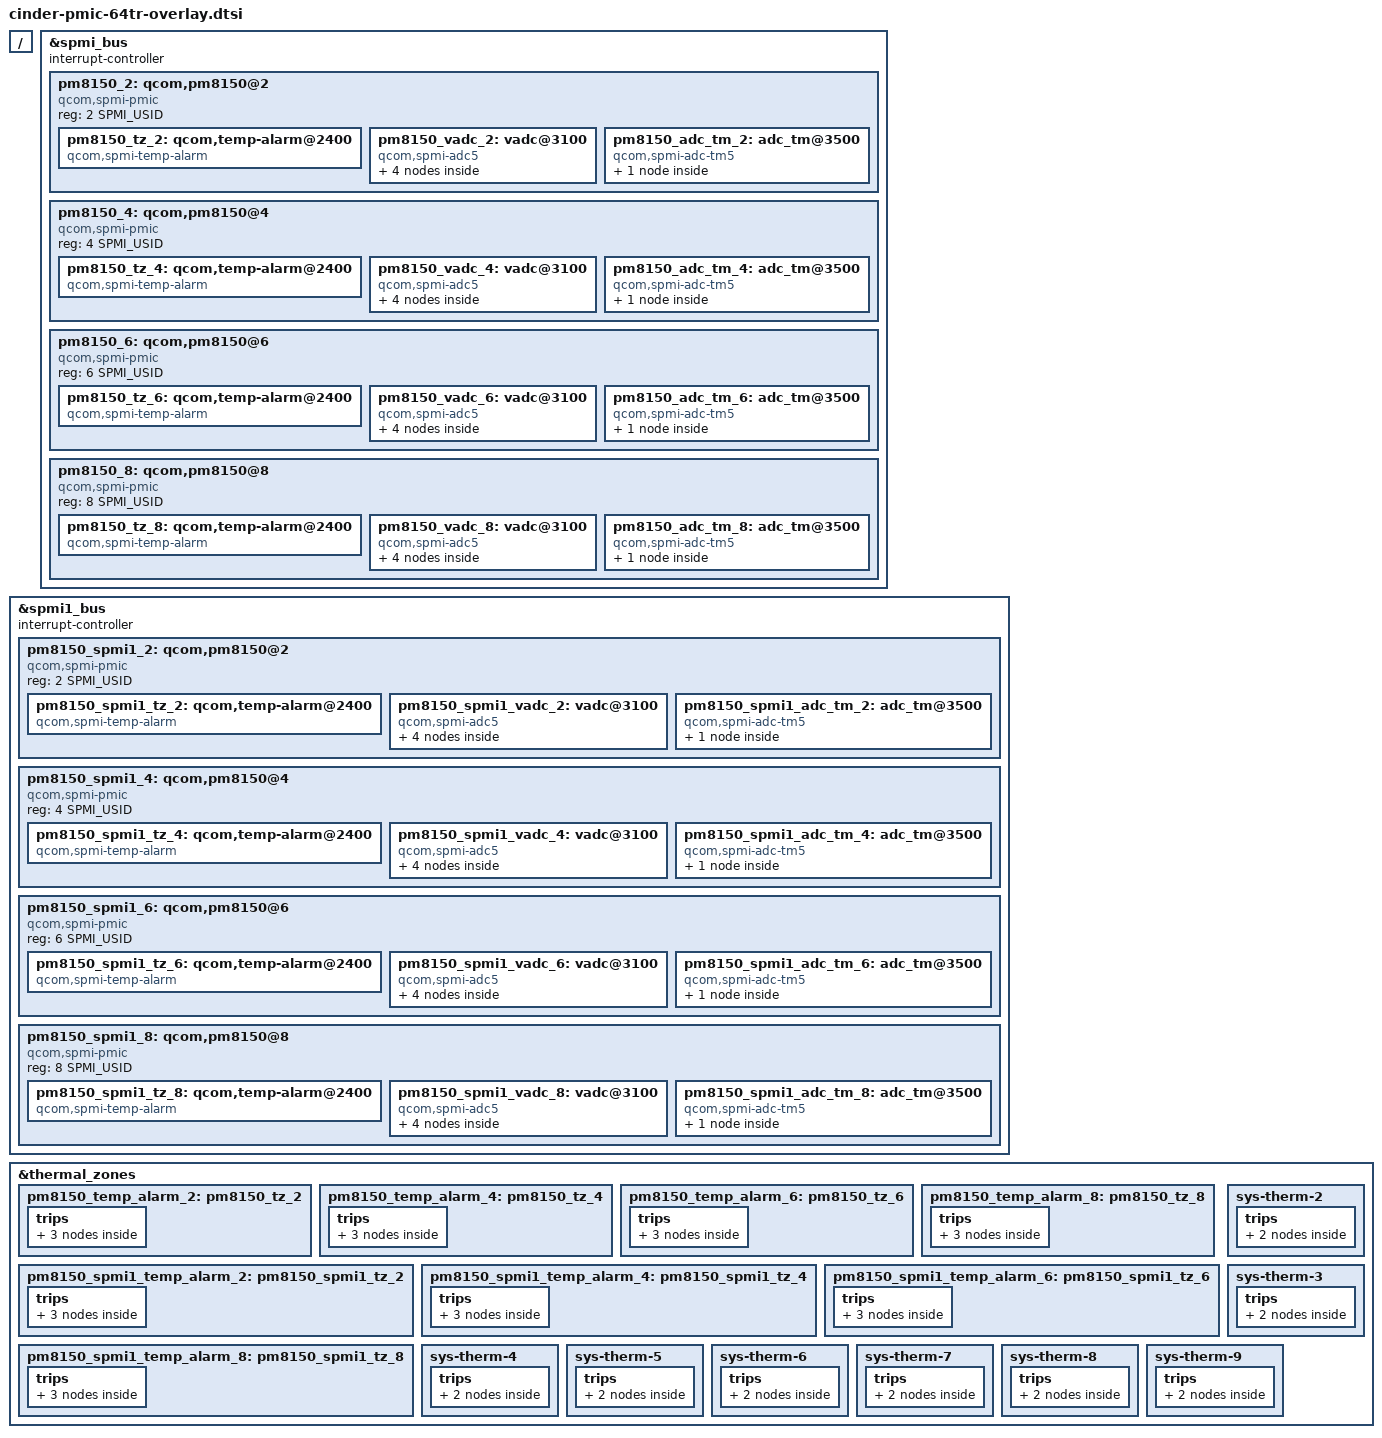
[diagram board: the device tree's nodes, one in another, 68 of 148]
/ {
	qcom,pmic-id-size = <8>;
	qcom,pmic-id = <0x1E 0x1E 0x1E 0x1E 0x1E 0x0 0x0 0x0>;
};

&spmi_bus {
	status = "ok";
	#address-cells = <2>;
	#size-cells = <0>;
	interrupt-controller;
	#interrupt-cells = <4>;

	pm8150_2: qcom,pm8150@2 {
		status = "okay";
		compatible = "qcom,spmi-pmic";
		reg = <2 SPMI_USID>;
		#address-cells = <1>;
		#size-cells = <0>;

		pm8150_tz_2: qcom,temp-alarm@2400 {
			compatible = "qcom,spmi-temp-alarm";
			reg = <0x2400>;
			interrupts = <0x2 0x24 0x0 IRQ_TYPE_EDGE_BOTH>;
			io-channels = <&pm8150_vadc_2 ADC5_DIE_TEMP>;
			io-channel-names = "thermal";
			#thermal-sensor-cells = <0>;
		};

		pm8150_vadc_2: vadc@3100 {
			status = "okay";
			compatible = "qcom,spmi-adc5";
			reg = <0x3100>;
			#address-cells = <1>;
			#size-cells = <0>;
			interrupts = <0x2 0x31 0x0 IRQ_TYPE_EDGE_RISING>;
			interrupt-names = "eoc-int-en-set";
			#io-channel-cells = <1>;
			io-channel-ranges;

			/* Channel node */
			ref_gnd {
				reg = <ADC5_REF_GND>;
				label = "ref_gnd";
				qcom,pre-scaling = <1 1>;
			};

			vref_1p25 {
				reg = <ADC5_1P25VREF>;
				label = "vref_1p25";
				qcom,pre-scaling = <1 1>;
			};

			die_temp {
				reg = <ADC5_DIE_TEMP>;
				label = "die_temp";
				qcom,pre-scaling = <1 1>;
			};
		};

		pm8150_adc_tm_2: adc_tm@3500 {
			status = "okay";
			compatible = "qcom,spmi-adc-tm5";
			reg = <0x3500>;
			interrupts = <0x2 0x35 0x0 IRQ_TYPE_EDGE_RISING>;
			interrupt-names = "threshold";
			#address-cells = <1>;
			#size-cells = <0>;
			#thermal-sensor-cells = <1>;
			io-channels = <&pm8150_vadc_2 ADC5_XO_THERM_100K_PU>,
					<&pm8150_vadc_2 ADC5_AMUX_THM1_100K_PU>,
					<&pm8150_vadc_2 ADC5_AMUX_THM2_100K_PU>;
		};
	};

	pm8150_4: qcom,pm8150@4 {
		status = "okay";
		compatible = "qcom,spmi-pmic";
		reg = <4 SPMI_USID>;
		#address-cells = <1>;
		#size-cells = <0>;

		pm8150_tz_4: qcom,temp-alarm@2400 {
			compatible = "qcom,spmi-temp-alarm";
			reg = <0x2400>;
			interrupts = <0x4 0x24 0x0 IRQ_TYPE_EDGE_BOTH>;
			io-channels = <&pm8150_vadc_4 ADC5_DIE_TEMP>;
			io-channel-names = "thermal";
			#thermal-sensor-cells = <0>;
		};

		pm8150_vadc_4: vadc@3100 {
			status = "okay";
			compatible = "qcom,spmi-adc5";
			reg = <0x3100>;
			#address-cells = <1>;
			#size-cells = <0>;
			interrupts = <0x4 0x31 0x0 IRQ_TYPE_EDGE_RISING>;
			interrupt-names = "eoc-int-en-set";
			#io-channel-cells = <1>;
			io-channel-ranges;

			/* Channel node */
			ref_gnd {
				reg = <ADC5_REF_GND>;
				label = "ref_gnd";
				qcom,pre-scaling = <1 1>;
			};

			vref_1p25 {
				reg = <ADC5_1P25VREF>;
				label = "vref_1p25";
				qcom,pre-scaling = <1 1>;
			};

			die_temp {
				reg = <ADC5_DIE_TEMP>;
				label = "die_temp";
				qcom,pre-scaling = <1 1>;
			};
		};

		pm8150_adc_tm_4: adc_tm@3500 {
			status = "okay";
			compatible = "qcom,spmi-adc-tm5";
			reg = <0x3500>;
			interrupts = <0x4 0x35 0x0 IRQ_TYPE_EDGE_RISING>;
			interrupt-names = "threshold";
			#address-cells = <1>;
			#size-cells = <0>;
			#thermal-sensor-cells = <1>;
			io-channels = <&pm8150_vadc_4 ADC5_XO_THERM_100K_PU>,
					<&pm8150_vadc_4 ADC5_AMUX_THM1_100K_PU>,
					<&pm8150_vadc_4 ADC5_AMUX_THM2_100K_PU>;
		};
	};

	pm8150_6: qcom,pm8150@6 {
		status = "okay";
		compatible = "qcom,spmi-pmic";
		reg = <6 SPMI_USID>;
		#address-cells = <1>;
		#size-cells = <0>;

		pm8150_tz_6: qcom,temp-alarm@2400 {
			compatible = "qcom,spmi-temp-alarm";
			reg = <0x2400>;
			interrupts = <0x6 0x24 0x0 IRQ_TYPE_EDGE_BOTH>;
			io-channels = <&pm8150_vadc_6 ADC5_DIE_TEMP>;
			io-channel-names = "thermal";
			#thermal-sensor-cells = <0>;
		};

		pm8150_vadc_6: vadc@3100 {
			status = "okay";
			compatible = "qcom,spmi-adc5";
			reg = <0x3100>;
			#address-cells = <1>;
			#size-cells = <0>;
			interrupts = <0x6 0x31 0x0 IRQ_TYPE_EDGE_RISING>;
			interrupt-names = "eoc-int-en-set";
			#io-channel-cells = <1>;
			io-channel-ranges;

			/* Channel node */
			ref_gnd {
				reg = <ADC5_REF_GND>;
				label = "ref_gnd";
				qcom,pre-scaling = <1 1>;
			};

			vref_1p25 {
				reg = <ADC5_1P25VREF>;
				label = "vref_1p25";
				qcom,pre-scaling = <1 1>;
			};

			die_temp {
				reg = <ADC5_DIE_TEMP>;
				label = "die_temp";
				qcom,pre-scaling = <1 1>;
			};
		};

		pm8150_adc_tm_6: adc_tm@3500 {
			status = "okay";
			compatible = "qcom,spmi-adc-tm5";
			reg = <0x3500>;
			interrupts = <0x6 0x35 0x0 IRQ_TYPE_EDGE_RISING>;
			interrupt-names = "threshold";
			#address-cells = <1>;
			#size-cells = <0>;
			#thermal-sensor-cells = <1>;
			io-channels = <&pm8150_vadc_6 ADC5_XO_THERM_100K_PU>,
					<&pm8150_vadc_6 ADC5_AMUX_THM1_100K_PU>,
					<&pm8150_vadc_6 ADC5_AMUX_THM2_100K_PU>;
		};
	};

	pm8150_8: qcom,pm8150@8 {
		status = "okay";
		compatible = "qcom,spmi-pmic";
		reg = <8 SPMI_USID>;
		#address-cells = <1>;
		#size-cells = <0>;

		pm8150_tz_8: qcom,temp-alarm@2400 {
			compatible = "qcom,spmi-temp-alarm";
			reg = <0x2400>;
			interrupts = <0x8 0x24 0x0 IRQ_TYPE_EDGE_BOTH>;
			io-channels = <&pm8150_vadc_8 ADC5_DIE_TEMP>;
			io-channel-names = "thermal";
			#thermal-sensor-cells = <0>;
		};

		pm8150_vadc_8: vadc@3100 {
			status = "okay";
			compatible = "qcom,spmi-adc5";
			reg = <0x3100>;
			#address-cells = <1>;
			#size-cells = <0>;
			interrupts = <0x8 0x31 0x0 IRQ_TYPE_EDGE_RISING>;
			interrupt-names = "eoc-int-en-set";
			#io-channel-cells = <1>;
			io-channel-ranges;

			/* Channel node */
			ref_gnd {
				reg = <ADC5_REF_GND>;
				label = "ref_gnd";
				qcom,pre-scaling = <1 1>;
			};

			vref_1p25 {
				reg = <ADC5_1P25VREF>;
				label = "vref_1p25";
				qcom,pre-scaling = <1 1>;
			};

			die_temp {
				reg = <ADC5_DIE_TEMP>;
				label = "die_temp";
				qcom,pre-scaling = <1 1>;
			};
		};

		pm8150_adc_tm_8: adc_tm@3500 {
			status = "okay";
			compatible = "qcom,spmi-adc-tm5";
			reg = <0x3500>;
			interrupts = <0x8 0x35 0x0 IRQ_TYPE_EDGE_RISING>;
			interrupt-names = "threshold";
			#address-cells = <1>;
			#size-cells = <0>;
			#thermal-sensor-cells = <1>;
			io-channels = <&pm8150_vadc_8 ADC5_XO_THERM_100K_PU>,
					<&pm8150_vadc_8 ADC5_AMUX_THM1_100K_PU>,
					<&pm8150_vadc_8 ADC5_AMUX_THM2_100K_PU>;
		};
	};
};

&spmi1_bus {
	status = "ok";
	#address-cells = <2>;
	#size-cells = <0>;
	interrupt-controller;
	#interrupt-cells = <4>;

	pm8150_spmi1_2: qcom,pm8150@2 {
		status = "okay";
		compatible = "qcom,spmi-pmic";
		reg = <2 SPMI_USID>;
		#address-cells = <1>;
		#size-cells = <0>;

		pm8150_spmi1_tz_2: qcom,temp-alarm@2400 {
			compatible = "qcom,spmi-temp-alarm";
			reg = <0x2400>;
			interrupts = <0x2 0x24 0x0 IRQ_TYPE_EDGE_BOTH>;
			io-channels = <&pm8150_spmi1_vadc_2 ADC5_DIE_TEMP>;
			io-channel-names = "thermal";
			#thermal-sensor-cells = <0>;
		};

		pm8150_spmi1_vadc_2: vadc@3100 {
			status = "okay";
			compatible = "qcom,spmi-adc5";
			reg = <0x3100>;
			#address-cells = <1>;
			#size-cells = <0>;
			interrupts = <0x2 0x31 0x0 IRQ_TYPE_EDGE_RISING>;
			interrupt-names = "eoc-int-en-set";
			#io-channel-cells = <1>;
			io-channel-ranges;

			/* Channel node */
			ref_gnd {
				reg = <ADC5_REF_GND>;
				label = "ref_gnd";
				qcom,pre-scaling = <1 1>;
			};

			vref_1p25 {
				reg = <ADC5_1P25VREF>;
				label = "vref_1p25";
				qcom,pre-scaling = <1 1>;
			};

			die_temp {
				reg = <ADC5_DIE_TEMP>;
				label = "die_temp";
				qcom,pre-scaling = <1 1>;
			};
		};

		pm8150_spmi1_adc_tm_2: adc_tm@3500 {
			status = "okay";
			compatible = "qcom,spmi-adc-tm5";
			reg = <0x3500>;
			interrupts = <0x2 0x35 0x0 IRQ_TYPE_EDGE_RISING>;
			interrupt-names = "threshold";
			#address-cells = <1>;
			#size-cells = <0>;
			#thermal-sensor-cells = <1>;
			io-channels = <&pm8150_spmi1_vadc_2 ADC5_XO_THERM_100K_PU>,
					<&pm8150_spmi1_vadc_2 ADC5_AMUX_THM1_100K_PU>,
					<&pm8150_spmi1_vadc_2 ADC5_AMUX_THM2_100K_PU>;
		};
	};

	pm8150_spmi1_4: qcom,pm8150@4 {
		status = "okay";
		compatible = "qcom,spmi-pmic";
		reg = <4 SPMI_USID>;
		#address-cells = <1>;
		#size-cells = <0>;

		pm8150_spmi1_tz_4: qcom,temp-alarm@2400 {
			compatible = "qcom,spmi-temp-alarm";
			reg = <0x2400>;
			interrupts = <0x4 0x24 0x0 IRQ_TYPE_EDGE_BOTH>;
			io-channels = <&pm8150_spmi1_vadc_4 ADC5_DIE_TEMP>;
			io-channel-names = "thermal";
			#thermal-sensor-cells = <0>;
		};

		pm8150_spmi1_vadc_4: vadc@3100 {
			status = "okay";
			compatible = "qcom,spmi-adc5";
			reg = <0x3100>;
			#address-cells = <1>;
			#size-cells = <0>;
			interrupts = <0x4 0x31 0x0 IRQ_TYPE_EDGE_RISING>;
			interrupt-names = "eoc-int-en-set";
			#io-channel-cells = <1>;
			io-channel-ranges;

			/* Channel node */
			ref_gnd {
				reg = <ADC5_REF_GND>;
				label = "ref_gnd";
				qcom,pre-scaling = <1 1>;
			};

			vref_1p25 {
				reg = <ADC5_1P25VREF>;
				label = "vref_1p25";
				qcom,pre-scaling = <1 1>;
			};

			die_temp {
				reg = <ADC5_DIE_TEMP>;
				label = "die_temp";
				qcom,pre-scaling = <1 1>;
			};
		};

		pm8150_spmi1_adc_tm_4: adc_tm@3500 {
			status = "okay";
			compatible = "qcom,spmi-adc-tm5";
			reg = <0x3500>;
			interrupts = <0x4 0x35 0x0 IRQ_TYPE_EDGE_RISING>;
			interrupt-names = "threshold";
			#address-cells = <1>;
			#size-cells = <0>;
			#thermal-sensor-cells = <1>;
			io-channels = <&pm8150_spmi1_vadc_4 ADC5_XO_THERM_100K_PU>,
					<&pm8150_spmi1_vadc_4 ADC5_AMUX_THM1_100K_PU>,
					<&pm8150_spmi1_vadc_4 ADC5_AMUX_THM2_100K_PU>;
		};
	   };

	pm8150_spmi1_6: qcom,pm8150@6 {
		status = "okay";
		compatible = "qcom,spmi-pmic";
		reg = <6 SPMI_USID>;
		#address-cells = <1>;
		#size-cells = <0>;

		pm8150_spmi1_tz_6: qcom,temp-alarm@2400 {
			compatible = "qcom,spmi-temp-alarm";
			reg = <0x2400>;
			interrupts = <0x6 0x24 0x0 IRQ_TYPE_EDGE_BOTH>;
			io-channels = <&pm8150_spmi1_vadc_6 ADC5_DIE_TEMP>;
			io-channel-names = "thermal";
			#thermal-sensor-cells = <0>;
		};

		pm8150_spmi1_vadc_6: vadc@3100 {
			status = "okay";
			compatible = "qcom,spmi-adc5";
			reg = <0x3100>;
			#address-cells = <1>;
			#size-cells = <0>;
			interrupts = <0x6 0x31 0x0 IRQ_TYPE_EDGE_RISING>;
			interrupt-names = "eoc-int-en-set";
			#io-channel-cells = <1>;
			io-channel-ranges;

			/* Channel node */
			ref_gnd {
				reg = <ADC5_REF_GND>;
				label = "ref_gnd";
				qcom,pre-scaling = <1 1>;
			};

			vref_1p25 {
				reg = <ADC5_1P25VREF>;
				label = "vref_1p25";
				qcom,pre-scaling = <1 1>;
			};

			die_temp {
				reg = <ADC5_DIE_TEMP>;
				label = "die_temp";
				qcom,pre-scaling = <1 1>;
			};
		};

		pm8150_spmi1_adc_tm_6: adc_tm@3500 {
			status = "okay";
			compatible = "qcom,spmi-adc-tm5";
			reg = <0x3500>;
			interrupts = <0x6 0x35 0x0 IRQ_TYPE_EDGE_RISING>;
			interrupt-names = "threshold";
			#address-cells = <1>;
			#size-cells = <0>;
			#thermal-sensor-cells = <1>;
			io-channels = <&pm8150_spmi1_vadc_6 ADC5_XO_THERM_100K_PU>,
					<&pm8150_spmi1_vadc_6 ADC5_AMUX_THM1_100K_PU>,
					<&pm8150_spmi1_vadc_6 ADC5_AMUX_THM2_100K_PU>;
		};
	};

	pm8150_spmi1_8: qcom,pm8150@8 {
		status = "okay";
		compatible = "qcom,spmi-pmic";
		reg = <8 SPMI_USID>;
		#address-cells = <1>;
		#size-cells = <0>;

		pm8150_spmi1_tz_8: qcom,temp-alarm@2400 {
			compatible = "qcom,spmi-temp-alarm";
			reg = <0x2400>;
			interrupts = <0x8 0x24 0x0 IRQ_TYPE_EDGE_BOTH>;
			io-channels = <&pm8150_spmi1_vadc_8 ADC5_DIE_TEMP>;
			io-channel-names = "thermal";
			#thermal-sensor-cells = <0>;
		};

		pm8150_spmi1_vadc_8: vadc@3100 {
			status = "okay";
			compatible = "qcom,spmi-adc5";
			reg = <0x3100>;
			#address-cells = <1>;
			#size-cells = <0>;
			interrupts = <0x8 0x31 0x0 IRQ_TYPE_EDGE_RISING>;
			interrupt-names = "eoc-int-en-set";
			#io-channel-cells = <1>;
			io-channel-ranges;

			/* Channel node */
			ref_gnd {
				reg = <ADC5_REF_GND>;
				label = "ref_gnd";
				qcom,pre-scaling = <1 1>;
			};

			vref_1p25 {
				reg = <ADC5_1P25VREF>;
				label = "vref_1p25";
				qcom,pre-scaling = <1 1>;
			};

			die_temp {
				reg = <ADC5_DIE_TEMP>;
				label = "die_temp";
				qcom,pre-scaling = <1 1>;
			};
		};

		pm8150_spmi1_adc_tm_8: adc_tm@3500 {
			status = "okay";
			compatible = "qcom,spmi-adc-tm5";
			reg = <0x3500>;
			interrupts = <0x8 0x35 0x0 IRQ_TYPE_EDGE_RISING>;
			interrupt-names = "threshold";
			#address-cells = <1>;
			#size-cells = <0>;
			#thermal-sensor-cells = <1>;
			io-channels = <&pm8150_spmi1_vadc_8 ADC5_XO_THERM_100K_PU>,
					<&pm8150_spmi1_vadc_8 ADC5_AMUX_THM1_100K_PU>,
					<&pm8150_spmi1_vadc_8 ADC5_AMUX_THM2_100K_PU>;
		};
	};
};

&thermal_zones {
	pm8150_temp_alarm_2: pm8150_tz_2 {
		polling-delay-passive = <100>;
		polling-delay = <0>;
		thermal-sensors = <&pm8150_tz_2>;

		trips {
			pm8150_2_trip0: trip0 {
				temperature = <105000>;
				hysteresis = <0>;
				type = "passive";
			};

			pm8150_2_trip1: trip1 {
				temperature = <125000>;
				hysteresis = <0>;
				type = "passive";
			};

			trip2 {
				temperature = <155000>;
				hysteresis = <0>;
				type = "critical";
			};
		};
	};

	pm8150_temp_alarm_4: pm8150_tz_4 {
		polling-delay-passive = <100>;
		polling-delay = <0>;
		thermal-sensors = <&pm8150_tz_4>;

		trips {
			pm8150_4_trip0: trip0 {
				temperature = <105000>;
				hysteresis = <0>;
				type = "passive";
			};

			pm8150_4_trip1: trip1 {
				temperature = <125000>;
				hysteresis = <0>;
				type = "passive";
			};

			trip2 {
				temperature = <155000>;
				hysteresis = <0>;
				type = "critical";
			};
		};
	};

	pm8150_temp_alarm_6: pm8150_tz_6 {
		polling-delay-passive = <100>;
		polling-delay = <0>;
		thermal-sensors = <&pm8150_tz_6>;

		trips {
			pm8150_6_trip0: trip0 {
				temperature = <105000>;
				hysteresis = <0>;
				type = "passive";
			};

			pm8150_6_trip1: trip1 {
				temperature = <125000>;
				hysteresis = <0>;
				type = "passive";
			};

			trip2 {
				temperature = <155000>;
				hysteresis = <0>;
				type = "critical";
			};
		};
	};

	pm8150_temp_alarm_8: pm8150_tz_8 {
		polling-delay-passive = <100>;
		polling-delay = <0>;
		thermal-sensors = <&pm8150_tz_8>;

		trips {
			pm8150_8_trip0: trip0 {
				temperature = <105000>;
				hysteresis = <0>;
				type = "passive";
			};

			pm8150_8_trip1: trip1 {
				temperature = <125000>;
				hysteresis = <0>;
				type = "passive";
			};

			trip2 {
				temperature = <155000>;
				hysteresis = <0>;
				type = "critical";
			};
		};
	};

	pm8150_spmi1_temp_alarm_2: pm8150_spmi1_tz_2 {
		polling-delay-passive = <100>;
		polling-delay = <0>;
		thermal-sensors = <&pm8150_spmi1_tz_2>;

		trips {
			pm8150_spmi1_2_trip0: trip0 {
				temperature = <105000>;
				hysteresis = <0>;
				type = "passive";
			};

			pm8150_spmi1_2_trip1: trip1 {
				temperature = <125000>;
				hysteresis = <0>;
				type = "passive";
			};

			trip2 {
				temperature = <155000>;
				hysteresis = <0>;
				type = "critical";
			};
		};
	};

	pm8150_spmi1_temp_alarm_4: pm8150_spmi1_tz_4 {
		polling-delay-passive = <100>;
		polling-delay = <0>;
		thermal-sensors = <&pm8150_spmi1_tz_4>;

		trips {
			pm8150_14_trip0: trip0 {
				temperature = <105000>;
				hysteresis = <0>;
				type = "passive";
			};

			pm8150_14_trip1: trip1 {
				temperature = <125000>;
				hysteresis = <0>;
				type = "passive";
			};

			trip2 {
				temperature = <155000>;
				hysteresis = <0>;
				type = "critical";
			};
		};
	};

	pm8150_spmi1_temp_alarm_6: pm8150_spmi1_tz_6 {
		polling-delay-passive = <100>;
		polling-delay = <0>;
		thermal-sensors = <&pm8150_spmi1_tz_6>;

		trips {
			pm8150_16_trip0: trip0 {
				temperature = <105000>;
				hysteresis = <0>;
				type = "passive";
			};

			pm8150_16_trip1: trip1 {
				temperature = <125000>;
				hysteresis = <0>;
				type = "passive";
			};

			trip2 {
				temperature = <155000>;
				hysteresis = <0>;
				type = "critical";
			};
		};
	};

	pm8150_spmi1_temp_alarm_8: pm8150_spmi1_tz_8 {
		polling-delay-passive = <100>;
		polling-delay = <0>;
		thermal-sensors = <&pm8150_spmi1_tz_8>;

		trips {
			pm8150_spmi1_8_trip0: trip0 {
				temperature = <105000>;
				hysteresis = <0>;
				type = "passive";
			};

			pm8150_spmi1_8_trip1: trip1 {
				temperature = <125000>;
				hysteresis = <0>;
				type = "passive";
			};

			trip2 {
				temperature = <155000>;
				hysteresis = <0>;
				type = "critical";
			};
		};
	};
};

&pm8150_vadc_2 {
	amux_therm1 {
		reg = <ADC5_AMUX_THM1_100K_PU>;
		label = "amux_therm1";
		qcom,ratiometric;
		qcom,hw-settle-time = <1>;
		qcom,pre-scaling = <1 1>;
	};
};

&pm8150_vadc_4 {
	amux_therm1 {
		reg = <ADC5_AMUX_THM1_100K_PU>;
		label = "amux_therm1";
		qcom,ratiometric;
		qcom,hw-settle-time = <1>;
		qcom,pre-scaling = <1 1>;
	};
};

&pm8150_vadc_6 {
	amux_therm1 {
		reg = <ADC5_AMUX_THM1_100K_PU>;
		label = "amux_therm1";
		qcom,ratiometric;
		qcom,hw-settle-time = <1>;
		qcom,pre-scaling = <1 1>;
	};
};

&pm8150_vadc_8 {
	amux_therm1 {
		reg = <ADC5_AMUX_THM1_100K_PU>;
		label = "amux_therm1";
		qcom,ratiometric;
		qcom,hw-settle-time = <1>;
		qcom,pre-scaling = <1 1>;
	};
};

&pm8150_spmi1_vadc_2 {
	amux_therm1 {
		reg = <ADC5_AMUX_THM1_100K_PU>;
		label = "amux_therm1";
		qcom,ratiometric;
		qcom,hw-settle-time = <1>;
		qcom,pre-scaling = <1 1>;
	};
};

&pm8150_spmi1_vadc_4 {
	amux_therm1 {
		reg = <ADC5_AMUX_THM1_100K_PU>;
		label = "amux_therm1";
		qcom,ratiometric;
		qcom,hw-settle-time = <1>;
		qcom,pre-scaling = <1 1>;
	};
};

&pm8150_spmi1_vadc_6 {
	amux_therm1 {
		reg = <ADC5_AMUX_THM1_100K_PU>;
		label = "amux_therm1";
		qcom,ratiometric;
		qcom,hw-settle-time = <1>;
		qcom,pre-scaling = <1 1>;
	};
};

&pm8150_spmi1_vadc_8 {
	amux_therm1 {
		reg = <ADC5_AMUX_THM1_100K_PU>;
		label = "amux_therm1";
		qcom,ratiometric;
		qcom,hw-settle-time = <1>;
		qcom,pre-scaling = <1 1>;
	};
};

&pm8150_adc_tm_2 {
	amux_therm1 {
		reg = <1>;
		io-channels = <&pm8150_vadc_2 ADC5_AMUX_THM1_100K_PU>;
		qcom,ratiometric;
		qcom,hw-settle-time = <1>;
	};
};

&pm8150_adc_tm_4 {
	amux_therm1 {
		reg = <1>;
		io-channels = <&pm8150_vadc_4 ADC5_AMUX_THM1_100K_PU>;
		qcom,ratiometric;
		qcom,hw-settle-time = <1>;
	};
};

&pm8150_adc_tm_6 {
	amux_therm1 {
		reg = <1>;
		io-channels = <&pm8150_vadc_6 ADC5_AMUX_THM1_100K_PU>;
		qcom,ratiometric;
		qcom,hw-settle-time = <1>;
	};
};

&pm8150_adc_tm_8 {
	amux_therm1 {
		reg = <1>;
		io-channels = <&pm8150_vadc_8 ADC5_AMUX_THM1_100K_PU>;
		qcom,ratiometric;
		qcom,hw-settle-time = <1>;
	};
};

&pm8150_spmi1_adc_tm_2 {
	amux_therm1 {
		reg = <1>;
		io-channels = <&pm8150_spmi1_vadc_2 ADC5_AMUX_THM1_100K_PU>;
		qcom,ratiometric;
		qcom,hw-settle-time = <1>;
	};
};

&pm8150_spmi1_adc_tm_4 {
	amux_therm1 {
		reg = <1>;
		io-channels = <&pm8150_spmi1_vadc_4 ADC5_AMUX_THM1_100K_PU>;
		qcom,ratiometric;
		qcom,hw-settle-time = <1>;
	};
};

&pm8150_spmi1_adc_tm_6 {
	amux_therm1 {
		reg = <1>;
		io-channels = <&pm8150_spmi1_vadc_6 ADC5_AMUX_THM1_100K_PU>;
		qcom,ratiometric;
		qcom,hw-settle-time = <1>;
	};
};

&pm8150_spmi1_adc_tm_8 {
	amux_therm1 {
		reg = <1>;
		io-channels = <&pm8150_spmi1_vadc_8 ADC5_AMUX_THM1_100K_PU>;
		qcom,ratiometric;
		qcom,hw-settle-time = <1>;
	};
};

&thermal_zones {
	sys-therm-2 {
		polling-delay-passive = <0>;
		polling-delay = <0>;
		thermal-sensors = <&pm8150_adc_tm_2 1>;
		trips {
			active-config0 {
				temperature = <125000>;
				hysteresis = <1000>;
				type = "passive";
			};

			active-config1 {
				temperature = <125000>;
				hysteresis = <1000>;
				type = "passive";
			};
		};
	};

	sys-therm-3 {
		polling-delay-passive = <0>;
		polling-delay = <0>;
		thermal-sensors = <&pm8150_adc_tm_4 1>;
		trips {
			active-config0 {
				temperature = <125000>;
				hysteresis = <1000>;
				type = "passive";
			};

			active-config1 {
				temperature = <125000>;
				hysteresis = <1000>;
				type = "passive";
			};
		};
	};

	sys-therm-4 {
		polling-delay-passive = <0>;
		polling-delay = <0>;
		thermal-sensors = <&pm8150_adc_tm_6 1>;
		trips {
			active-config0 {
				temperature = <125000>;
				hysteresis = <1000>;
				type = "passive";
			};

			active-config1 {
				temperature = <125000>;
				hysteresis = <1000>;
				type = "passive";
			};
		};
	};

	sys-therm-5 {
		polling-delay-passive = <0>;
		polling-delay = <0>;
		thermal-sensors = <&pm8150_adc_tm_8 1>;
		trips {
			active-config0 {
				temperature = <125000>;
				hysteresis = <1000>;
				type = "passive";
			};

			active-config1 {
				temperature = <125000>;
				hysteresis = <1000>;
				type = "passive";
			};
		};
	};

	sys-therm-6 {
		polling-delay-passive = <0>;
		polling-delay = <0>;
		thermal-sensors = <&pm8150_spmi1_adc_tm_2 1>;
		trips {
			active-config0 {
				temperature = <125000>;
				hysteresis = <1000>;
				type = "passive";
			};

			active-config1 {
				temperature = <125000>;
				hysteresis = <1000>;
				type = "passive";
			};
		};
	};

	sys-therm-7 {
		polling-delay-passive = <0>;
		polling-delay = <0>;
		thermal-sensors = <&pm8150_spmi1_adc_tm_4 1>;
		trips {
			active-config0 {
				temperature = <125000>;
				hysteresis = <1000>;
				type = "passive";
			};

			active-config1 {
				temperature = <125000>;
				hysteresis = <1000>;
				type = "passive";
			};
		};
	};

	sys-therm-8 {
		polling-delay-passive = <0>;
		polling-delay = <0>;
		thermal-sensors = <&pm8150_spmi1_adc_tm_6 1>;
		trips {
			active-config0 {
				temperature = <125000>;
				hysteresis = <1000>;
				type = "passive";
			};

			active-config1 {
				temperature = <125000>;
				hysteresis = <1000>;
				type = "passive";
			};
		};
	};

	sys-therm-9 {
		polling-delay-passive = <0>;
		polling-delay = <0>;
		thermal-sensors = <&pm8150_spmi1_adc_tm_8 1>;
		trips {
			active-config0 {
				temperature = <125000>;
				hysteresis = <1000>;
				type = "passive";
			};

			active-config1 {
				temperature = <125000>;
				hysteresis = <1000>;
				type = "passive";
			};
		};
	};
};
